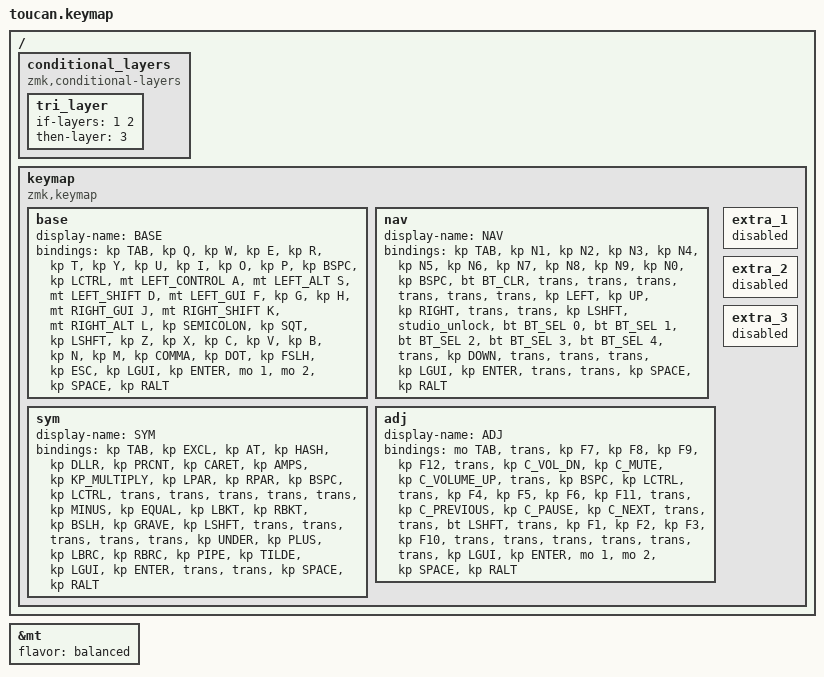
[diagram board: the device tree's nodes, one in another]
#include <behaviors.dtsi>
#include <dt-bindings/zmk/bt.h>
#include <dt-bindings/zmk/keys.h>

#define BASE 0
#define NAV  1
#define SYM  2
#define ADJ  3

&mt { flavor = "balanced"; };

/ {
    conditional_layers {
        compatible = "zmk,conditional-layers";

        tri_layer {
            if-layers = <1 2>;
            then-layer = <3>;
        };
    };

    keymap {
        compatible = "zmk,keymap";

        base {
            display-name = "BASE";
            bindings = <
&kp TAB  &kp Q  &kp W  &kp E  &kp R  &kp T  &kp Y  &kp U  &kp I  &kp O  &kp P  &kp BSPC  &kp LCTRL  &mt LEFT_CONTROL A  &mt LEFT_ALT S  &mt LEFT_SHIFT D  &mt LEFT_GUI F  &kp G  &kp H  &mt RIGHT_GUI J  &mt RIGHT_SHIFT K  &mt RIGHT_ALT L  &kp SEMICOLON  &kp SQT  &kp LSHFT  &kp Z  &kp X  &kp C  &kp V  &kp B  &kp N  &kp M  &kp COMMA  &kp DOT  &kp FSLH  &kp ESC  &kp LGUI  &kp ENTER  &mo 1  &mo 2  &kp SPACE  &kp RALT
            >;
        };

        nav {
            display-name = "NAV";
            bindings = <
&kp TAB  &kp N1  &kp N2  &kp N3  &kp N4  &kp N5  &kp N6  &kp N7  &kp N8  &kp N9  &kp N0  &kp BSPC  &bt BT_CLR  &trans  &trans  &trans  &trans  &trans  &trans  &kp LEFT  &kp UP  &kp RIGHT  &trans  &trans  &kp LSHFT  &studio_unlock  &bt BT_SEL 0  &bt BT_SEL 1  &bt BT_SEL 2  &bt BT_SEL 3  &bt BT_SEL 4  &trans  &kp DOWN  &trans  &trans  &trans  &kp LGUI  &kp ENTER  &trans  &trans  &kp SPACE  &kp RALT
            >;
        };

        sym {
            display-name = "SYM";
            bindings = <
&kp TAB  &kp EXCL  &kp AT  &kp HASH  &kp DLLR  &kp PRCNT  &kp CARET  &kp AMPS  &kp KP_MULTIPLY  &kp LPAR  &kp RPAR  &kp BSPC  &kp LCTRL  &trans  &trans  &trans  &trans  &trans  &kp MINUS  &kp EQUAL  &kp LBKT  &kp RBKT  &kp BSLH  &kp GRAVE  &kp LSHFT  &trans  &trans  &trans  &trans  &trans  &kp UNDER  &kp PLUS  &kp LBRC  &kp RBRC  &kp PIPE  &kp TILDE  &kp LGUI  &kp ENTER  &trans  &trans  &kp SPACE  &kp RALT
            >;
        };

        adj {
            display-name = "ADJ";
            bindings = <
&mo TAB  &trans  &kp F7  &kp F8  &kp F9  &kp F12  &trans  &kp C_VOL_DN  &kp C_MUTE  &kp C_VOLUME_UP  &trans  &kp BSPC  &kp LCTRL  &trans  &kp F4  &kp F5  &kp F6  &kp F11  &trans  &kp C_PREVIOUS  &kp C_PAUSE  &kp C_NEXT  &trans  &trans  &bt LSHFT  &trans  &kp F1  &kp F2  &kp F3  &kp F10  &trans  &trans  &trans  &trans  &trans  &trans  &kp LGUI  &kp ENTER  &mo 1  &mo 2  &kp SPACE  &kp RALT
            >;
        };

        extra_1 { status = "reserved"; };

        extra_2 { status = "reserved"; };

        extra_3 { status = "reserved"; };
    };
};
